VERSION ""

NS_ :

BS_:

BU_: DBG MASTER MOTOR SENSORS GEO BT
BO_ 95 HB_SENSOR: 1 SENSORS
 SG_ SENSORS_ALIVE : 0|1@1+ (1,0) [0|0] "" MASTER

BO_ 96 HB_MOTORS: 1 MOTOR
 SG_ MOTOR_ALIVE : 0|1@1+ (1,0) [0|0] "HB-M" MASTER,GEO,BT

BO_ 97 HB_GEO: 1 GEO
 SG_ GEO_ALIVE : 0|1@1+ (1,0) [0|0] "HB-G" MASTER,MOTOR,BT

BO_ 98 HB_BT: 1 BT
 SG_ BT_ALIVE : 0|1@1+ (1,0) [0|0] "HB-BT" MASTER,MOTOR,GEO

BO_ 99 HB_MASTER: 1 MASTER
 SG_ MASTER_ALIVE : 0|1@1+ (1,0) [0|0] "HB-MT" BT,MOTOR,GEO

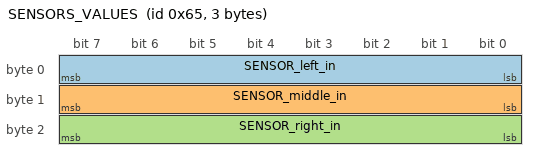
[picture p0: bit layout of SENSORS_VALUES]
BO_ 101 SENSORS_VALUES: 3 SENSORS
 SG_ SENSOR_left_in : 0|8@1+ (1,0) [0|0] "Inches" MASTER
 SG_ SENSOR_middle_in : 8|8@1+ (1,0) [0|0] "Inches" MASTER
 SG_ SENSOR_right_in : 16|8@1+ (1,0) [0|0] "Inches" MASTER

BO_ 200 MASTER_INITIALIZE: 1 MASTER
 SG_ MASTER_Init_Boards : 0|8@1+ (1,0) [0|0] "" SENSORS, MOTOR, BT, GEO

BO_ 201 MASTER_CURRENT_DIRECTION: 1 MASTER
 SG_ MASTER_Get_Direction : 0|8@1+ (1,0) [0|0] "" GEO

BO_ 202 MASTER_CURRENT_COORDINATES: 1 MASTER
 SG_ MASTER_Get_COORDINATES : 0|8@1+ (1,0) [0|0] "" GEO

BO_ 203 MASTER_SPEED: 1 MASTER
 SG_ MASTER_Maintain_Speed : 0|8@1+ (1,0) [0|30] "mph" MOTOR

BO_ 204 MASTER_DIRECTION: 1 MASTER
 SG_ MASTER_Maintain_Direction : 0|8@1+ (1,0) [0|12] "" MOTOR

BO_ 301 MOTOR_STATUS: 1 MOTOR
 SG_ MOTOR_Send_Speed : 0|8@1+ (0.1,0) [0|0] "mph" MASTER

BO_ 400 SEND_COORDINATES: 8 GEO
 SG_ SEND_LATTITUDE : 0|30@1+ (0.000001,-180) [-180|180] "DEGREE" MASTER
 SG_ SEND_LONGITUDE : 30|30@1+ (0.000001,-180) [-180|180] "DEGREE" MASTER

BO_ 500 GET_START_COORDINATES: 1 BT
 SG_ GET_COORDINATES : 0|4@1+ (1,0) [0|0] "" MASTER,GEO

BO_ 503 GET_ROUTE_COORDINATES: 8 BT
 SG_ SET_LATTITUDE : 0|30@1+ (0.000001,-180) [-180|180] "DEGREE" MASTER
 SG_ SET_LONGITUDE : 30|30@1+ (0.000001,-180) [-180|180] "DEGREE" MASTER
